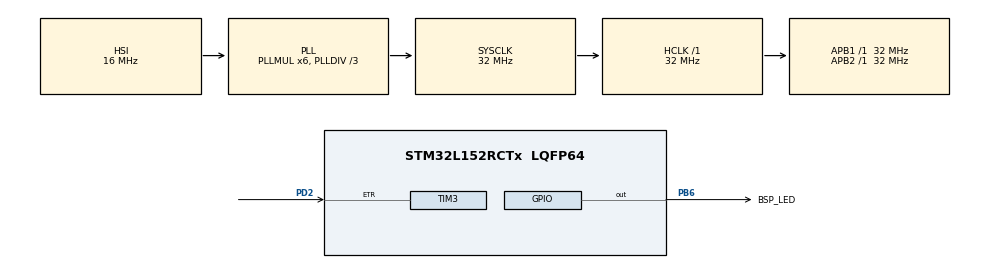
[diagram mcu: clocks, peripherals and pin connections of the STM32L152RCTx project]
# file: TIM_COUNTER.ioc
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Mcu.Family=STM32L1
Mcu.Name=STM32L152RCTx
Mcu.Package=LQFP64
NVIC.PriorityGroup=NVIC_PRIORITYGROUP_0
NVIC.TIM3_IRQn=true\:0\:0\:false\:false\:true\:true\:true\:true
PA13.Mode=Serial_Wire
PA13.Signal=SYS_JTMS-SWDIO
PA14.Mode=Serial_Wire
PA14.Signal=SYS_JTCK-SWCLK
PB6.GPIO_Label=BSP_LED
PB6.Signal=GPIO_Output
PC14-OSC32_IN.Mode=LSE-External-Oscillator
PC14-OSC32_IN.Signal=RCC_OSC32_IN
PC15-OSC32_OUT.Mode=LSE-External-Oscillator
PC15-OSC32_OUT.Signal=RCC_OSC32_OUT
PD2.Signal=S_TIM3_ETR
PH0-OSC_IN.Mode=HSE-External-Oscillator
PH0-OSC_IN.Signal=RCC_OSC_IN
PH1-OSC_OUT.Mode=HSE-External-Oscillator
PH1-OSC_OUT.Signal=RCC_OSC_OUT
ProjectManager.HeapSize=0x200
ProjectManager.StackSize=0x400
ProjectManager.TargetToolchain=STM32CubeIDE
RCC.48MHZClocksFreq_Value=48000000
RCC.AHBFreq_Value=32000000
RCC.APB1Freq_Value=32000000
RCC.APB1TimFreq_Value=32000000
RCC.APB2Freq_Value=32000000
RCC.APB2TimFreq_Value=32000000
RCC.HCLKFreq_Value=32000000
RCC.HSE_VALUE=8000000
RCC.HSI_VALUE=16000000
RCC.MSI_VALUE=2097000
RCC.PLLDIV=RCC_PLL_DIV3
RCC.PLLMUL=RCC_PLL_MUL6
RCC.RTCClockSelectionVirtual=RCC_RTCCLKSOURCE_LSE
RCC.SYSCLKFreq_VALUE=32000000
RCC.SYSCLKSource=RCC_SYSCLKSOURCE_PLLCLK
RCC.USBOutput=48000000
RCC.VCOOutputFreq_Value=96000000
SH.S_TIM3_ETR.0=TIM3_ETR,ClockSourceETR_Mode2
TIM3.CounterMode=TIM_COUNTERMODE_UP
TIM3.Period=5
board=STM32L152C-DISCO

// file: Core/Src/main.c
/* USER CODE BEGIN Header */
/**
  ******************************************************************************
  * @file           : main.c
  * @brief          : Main program body
  ******************************************************************************
  * @attention
  *
  * Copyright (c) 2023 STMicroelectronics.
  * All rights reserved.
  *
  * This software is licensed under terms that can be found in the LICENSE file
  * in the root directory of this software component.
  * If no LICENSE file comes with this software, it is provided AS-IS.
  *
  ******************************************************************************
  */
/* USER CODE END Header */
#include "main.h"

TIM_HandleTypeDef htim3;

void SystemClock_Config(void);
static void MX_GPIO_Init(void);
static void MX_TIM3_Init(void);

/* USER CODE BEGIN 0 */
void HAL_TIM_PeriodElapsedCallback(TIM_HandleTypeDef *htim){
	HAL_GPIO_TogglePin(BSP_LED_GPIO_Port,BSP_LED_Pin);
}

/* USER CODE END 0 */

int main(void)
{

  /* MCU Configuration--------------------------------------------------------*/

  /* Reset of all peripherals, Initializes the Flash interface and the Systick. */
  HAL_Init();

  /* Configure the system clock */
  SystemClock_Config();

  /* Initialize all configured peripherals */
  MX_GPIO_Init();
  MX_TIM3_Init();
  /* USER CODE BEGIN 2 */

  HAL_TIM_Base_Start_IT(&htim3);

  /* USER CODE END 2 */

  /* Infinite loop */
  while (1)
  {

  }
}

void SystemClock_Config(void)
{
  RCC_OscInitTypeDef RCC_OscInitStruct = {0};
  RCC_ClkInitTypeDef RCC_ClkInitStruct = {0};

  /** Configure the main internal regulator output voltage
  */
  __HAL_PWR_VOLTAGESCALING_CONFIG(PWR_REGULATOR_VOLTAGE_SCALE1);

  /** Initializes the RCC Oscillators according to the specified parameters
  * in the RCC_OscInitTypeDef structure.
  */
  RCC_OscInitStruct.OscillatorType = RCC_OSCILLATORTYPE_HSI;
  RCC_OscInitStruct.HSIState = RCC_HSI_ON;
  RCC_OscInitStruct.HSICalibrationValue = RCC_HSICALIBRATION_DEFAULT;
  RCC_OscInitStruct.PLL.PLLState = RCC_PLL_ON;
  RCC_OscInitStruct.PLL.PLLSource = RCC_PLLSOURCE_HSI;
  RCC_OscInitStruct.PLL.PLLMUL = RCC_PLL_MUL6;
  RCC_OscInitStruct.PLL.PLLDIV = RCC_PLL_DIV3;
  if (HAL_RCC_OscConfig(&RCC_OscInitStruct) != HAL_OK)
  {
    Error_Handler();
  }

  /** Initializes the CPU, AHB and APB buses clocks
  */
  RCC_ClkInitStruct.ClockType = RCC_CLOCKTYPE_HCLK|RCC_CLOCKTYPE_SYSCLK
                              |RCC_CLOCKTYPE_PCLK1|RCC_CLOCKTYPE_PCLK2;
  RCC_ClkInitStruct.SYSCLKSource = RCC_SYSCLKSOURCE_PLLCLK;
  RCC_ClkInitStruct.AHBCLKDivider = RCC_SYSCLK_DIV1;
  RCC_ClkInitStruct.APB1CLKDivider = RCC_HCLK_DIV1;
  RCC_ClkInitStruct.APB2CLKDivider = RCC_HCLK_DIV1;

  if (HAL_RCC_ClockConfig(&RCC_ClkInitStruct, FLASH_LATENCY_1) != HAL_OK)
  {
    Error_Handler();
  }
}

static void MX_TIM3_Init(void)
{

  TIM_ClockConfigTypeDef sClockSourceConfig = {0};
  TIM_MasterConfigTypeDef sMasterConfig = {0};

  htim3.Instance = TIM3;
  htim3.Init.Prescaler = 0;
  htim3.Init.CounterMode = TIM_COUNTERMODE_UP;
  htim3.Init.Period = 5;
  htim3.Init.ClockDivision = TIM_CLOCKDIVISION_DIV1;
  htim3.Init.AutoReloadPreload = TIM_AUTORELOAD_PRELOAD_DISABLE;
  if (HAL_TIM_Base_Init(&htim3) != HAL_OK)
  {
    Error_Handler();
  }
  sClockSourceConfig.ClockSource = TIM_CLOCKSOURCE_ETRMODE2;
  sClockSourceConfig.ClockPolarity = TIM_CLOCKPOLARITY_NONINVERTED;
  sClockSourceConfig.ClockPrescaler = TIM_CLOCKPRESCALER_DIV1;
  sClockSourceConfig.ClockFilter = 0;
  if (HAL_TIM_ConfigClockSource(&htim3, &sClockSourceConfig) != HAL_OK)
  {
    Error_Handler();
  }
  sMasterConfig.MasterOutputTrigger = TIM_TRGO_RESET;
  sMasterConfig.MasterSlaveMode = TIM_MASTERSLAVEMODE_DISABLE;
  if (HAL_TIMEx_MasterConfigSynchronization(&htim3, &sMasterConfig) != HAL_OK)
  {
    Error_Handler();
  }

}

static void MX_GPIO_Init(void)
{
  GPIO_InitTypeDef GPIO_InitStruct = {0};

  /* GPIO Ports Clock Enable */
  __HAL_RCC_GPIOC_CLK_ENABLE();
  __HAL_RCC_GPIOH_CLK_ENABLE();
  __HAL_RCC_GPIOA_CLK_ENABLE();
  __HAL_RCC_GPIOD_CLK_ENABLE();
  __HAL_RCC_GPIOB_CLK_ENABLE();

  /*Configure GPIO pin Output Level */
  HAL_GPIO_WritePin(BSP_LED_GPIO_Port, BSP_LED_Pin, GPIO_PIN_RESET);

  /*Configure GPIO pin : BSP_LED_Pin */
  GPIO_InitStruct.Pin = BSP_LED_Pin;
  GPIO_InitStruct.Mode = GPIO_MODE_OUTPUT_PP;
  GPIO_InitStruct.Pull = GPIO_NOPULL;
  GPIO_InitStruct.Speed = GPIO_SPEED_FREQ_LOW;
  HAL_GPIO_Init(BSP_LED_GPIO_Port, &GPIO_InitStruct);

}

void Error_Handler(void)
{
  __disable_irq();
  while (1)
  {
  }
}
